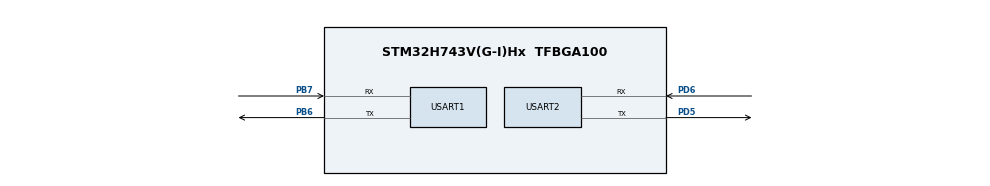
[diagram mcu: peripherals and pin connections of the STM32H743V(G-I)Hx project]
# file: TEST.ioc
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Mcu.Family=STM32H7
Mcu.Name=STM32H743V(G-I)Hx
Mcu.Package=TFBGA100
NVIC.PriorityGroup=NVIC_PRIORITYGROUP_4
NVIC.USART1_IRQn=true\:0\:0\:false\:false\:true\:true\:true\:true
NVIC.USART2_IRQn=true\:0\:0\:false\:false\:true\:true\:true\:true
PA13\ (JTMS/SWDIO).Mode=Serial_Wire
PA13\ (JTMS/SWDIO).Signal=DEBUG_JTMS-SWDIO
PA14\ (JTCK/SWCLK).Mode=Serial_Wire
PA14\ (JTCK/SWCLK).Signal=DEBUG_JTCK-SWCLK
PB6.Mode=Asynchronous
PB6.Signal=USART1_TX
PB7.Mode=Asynchronous
PB7.Signal=USART1_RX
PD5.Mode=Asynchronous
PD5.Signal=USART2_TX
PD6.Mode=Asynchronous
PD6.Signal=USART2_RX
PH0-OSC_IN\ (PH0).Mode=HSE-External-Oscillator
PH0-OSC_IN\ (PH0).Signal=RCC_OSC_IN
PH1-OSC_OUT\ (PH1).Mode=HSE-External-Oscillator
PH1-OSC_OUT\ (PH1).Signal=RCC_OSC_OUT
ProjectManager.HeapSize=0x200
ProjectManager.StackSize=0x400
ProjectManager.TargetToolchain=STM32CubeIDE
RCC.ADCFreq_Value=129000000
RCC.APB1Freq_Value=25000000
RCC.APB2Freq_Value=25000000
RCC.APB3Freq_Value=25000000
RCC.APB4Freq_Value=25000000
RCC.CortexFreq_Value=100000000
RCC.D1PPRE=RCC_APB3_DIV2
RCC.D2PPRE1=RCC_APB1_DIV2
RCC.D2PPRE2=RCC_APB2_DIV2
RCC.D3PPRE=RCC_APB4_DIV2
RCC.DIVM1=4
RCC.DIVN1=12
RCC.HCLKFreq_Value=50000000
RCC.HPRE=RCC_HCLK_DIV2
RCC.HSE_VALUE=25000000
RCC.PLL2FRACN=0
RCC.PLL3FRACN=0
RCC.PLLFRACN=4096
RCC.SYSCLKFreq_VALUE=100000000
RCC.SYSCLKSource=RCC_SYSCLKSOURCE_PLLCLK
RCC.USBFreq_Value=100000000
USART1.VirtualMode-Asynchronous=VM_ASYNC
USART2.VirtualMode-Asynchronous=VM_ASYNC
board=custom

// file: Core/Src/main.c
/* USER CODE BEGIN Header */
/**
  ******************************************************************************
  * @file           : main.c
  * @brief          : Main program body
  ******************************************************************************
  * @attention
  *
  * Copyright (c) 2024 STMicroelectronics.
  * All rights reserved.
  *
  * This software is licensed under terms that can be found in the LICENSE file
  * in the root directory of this software component.
  * If no LICENSE file comes with this software, it is provided AS-IS.
  *
  ******************************************************************************
  */
/* USER CODE END Header */
#include "main.h"

UART_HandleTypeDef huart1;
UART_HandleTypeDef huart2;

void SystemClock_Config(void);
static void MX_GPIO_Init(void);
static void MX_USART1_UART_Init(void);
static void MX_USART2_UART_Init(void);

/* USER CODE BEGIN 0 */
uint8_t usart1_buf[6];

/* USER CODE END 0 */

int main(void)
{

  /* MCU Configuration--------------------------------------------------------*/

  /* Reset of all peripherals, Initializes the Flash interface and the Systick. */
  HAL_Init();

  /* Configure the system clock */
  SystemClock_Config();

  /* Initialize all configured peripherals */
  MX_GPIO_Init();
  MX_USART1_UART_Init();
  MX_USART2_UART_Init();

  /* Infinite loop */
  while (1)
  {

  }
}

void SystemClock_Config(void)
{
  RCC_OscInitTypeDef RCC_OscInitStruct = {0};
  RCC_ClkInitTypeDef RCC_ClkInitStruct = {0};

  /** Supply configuration update enable
  */
  HAL_PWREx_ConfigSupply(PWR_LDO_SUPPLY);

  /** Configure the main internal regulator output voltage
  */
  __HAL_PWR_VOLTAGESCALING_CONFIG(PWR_REGULATOR_VOLTAGE_SCALE3);

  while(!__HAL_PWR_GET_FLAG(PWR_FLAG_VOSRDY)) {}

  /** Initializes the RCC Oscillators according to the specified parameters
  * in the RCC_OscInitTypeDef structure.
  */
  RCC_OscInitStruct.OscillatorType = RCC_OSCILLATORTYPE_HSI;
  RCC_OscInitStruct.HSIState = RCC_HSI_DIV1;
  RCC_OscInitStruct.HSICalibrationValue = RCC_HSICALIBRATION_DEFAULT;
  RCC_OscInitStruct.PLL.PLLState = RCC_PLL_ON;
  RCC_OscInitStruct.PLL.PLLSource = RCC_PLLSOURCE_HSI;
  RCC_OscInitStruct.PLL.PLLM = 4;
  RCC_OscInitStruct.PLL.PLLN = 12;
  RCC_OscInitStruct.PLL.PLLP = 2;
  RCC_OscInitStruct.PLL.PLLQ = 2;
  RCC_OscInitStruct.PLL.PLLR = 2;
  RCC_OscInitStruct.PLL.PLLRGE = RCC_PLL1VCIRANGE_3;
  RCC_OscInitStruct.PLL.PLLVCOSEL = RCC_PLL1VCOWIDE;
  RCC_OscInitStruct.PLL.PLLFRACN = 4096;
  if (HAL_RCC_OscConfig(&RCC_OscInitStruct) != HAL_OK)
  {
    Error_Handler();
  }

  /** Initializes the CPU, AHB and APB buses clocks
  */
  RCC_ClkInitStruct.ClockType = RCC_CLOCKTYPE_HCLK|RCC_CLOCKTYPE_SYSCLK
                              |RCC_CLOCKTYPE_PCLK1|RCC_CLOCKTYPE_PCLK2
                              |RCC_CLOCKTYPE_D3PCLK1|RCC_CLOCKTYPE_D1PCLK1;
  RCC_ClkInitStruct.SYSCLKSource = RCC_SYSCLKSOURCE_PLLCLK;
  RCC_ClkInitStruct.SYSCLKDivider = RCC_SYSCLK_DIV1;
  RCC_ClkInitStruct.AHBCLKDivider = RCC_HCLK_DIV2;
  RCC_ClkInitStruct.APB3CLKDivider = RCC_APB3_DIV2;
  RCC_ClkInitStruct.APB1CLKDivider = RCC_APB1_DIV2;
  RCC_ClkInitStruct.APB2CLKDivider = RCC_APB2_DIV2;
  RCC_ClkInitStruct.APB4CLKDivider = RCC_APB4_DIV2;

  if (HAL_RCC_ClockConfig(&RCC_ClkInitStruct, FLASH_LATENCY_1) != HAL_OK)
  {
    Error_Handler();
  }
}

static void MX_USART1_UART_Init(void)
{

  huart1.Instance = USART1;
  huart1.Init.BaudRate = 115200;
  huart1.Init.WordLength = UART_WORDLENGTH_8B;
  huart1.Init.StopBits = UART_STOPBITS_1;
  huart1.Init.Parity = UART_PARITY_NONE;
  huart1.Init.Mode = UART_MODE_TX_RX;
  huart1.Init.HwFlowCtl = UART_HWCONTROL_NONE;
  huart1.Init.OverSampling = UART_OVERSAMPLING_16;
  huart1.Init.OneBitSampling = UART_ONE_BIT_SAMPLE_DISABLE;
  huart1.Init.ClockPrescaler = UART_PRESCALER_DIV1;
  huart1.AdvancedInit.AdvFeatureInit = UART_ADVFEATURE_NO_INIT;
  if (HAL_UART_Init(&huart1) != HAL_OK)
  {
    Error_Handler();
  }
  if (HAL_UARTEx_SetTxFifoThreshold(&huart1, UART_TXFIFO_THRESHOLD_1_8) != HAL_OK)
  {
    Error_Handler();
  }
  if (HAL_UARTEx_SetRxFifoThreshold(&huart1, UART_RXFIFO_THRESHOLD_1_8) != HAL_OK)
  {
    Error_Handler();
  }
  if (HAL_UARTEx_DisableFifoMode(&huart1) != HAL_OK)
  {
    Error_Handler();
  }

}

static void MX_USART2_UART_Init(void)
{

  huart2.Instance = USART2;
  huart2.Init.BaudRate = 115200;
  huart2.Init.WordLength = UART_WORDLENGTH_8B;
  huart2.Init.StopBits = UART_STOPBITS_1;
  huart2.Init.Parity = UART_PARITY_NONE;
  huart2.Init.Mode = UART_MODE_TX_RX;
  huart2.Init.HwFlowCtl = UART_HWCONTROL_NONE;
  huart2.Init.OverSampling = UART_OVERSAMPLING_16;
  huart2.Init.OneBitSampling = UART_ONE_BIT_SAMPLE_DISABLE;
  huart2.Init.ClockPrescaler = UART_PRESCALER_DIV1;
  huart2.AdvancedInit.AdvFeatureInit = UART_ADVFEATURE_NO_INIT;
  if (HAL_UART_Init(&huart2) != HAL_OK)
  {
    Error_Handler();
  }
  if (HAL_UARTEx_SetTxFifoThreshold(&huart2, UART_TXFIFO_THRESHOLD_1_8) != HAL_OK)
  {
    Error_Handler();
  }
  if (HAL_UARTEx_SetRxFifoThreshold(&huart2, UART_RXFIFO_THRESHOLD_1_8) != HAL_OK)
  {
    Error_Handler();
  }
  if (HAL_UARTEx_DisableFifoMode(&huart2) != HAL_OK)
  {
    Error_Handler();
  }

}

static void MX_GPIO_Init(void)
{

  /* GPIO Ports Clock Enable */
  __HAL_RCC_GPIOB_CLK_ENABLE();
  __HAL_RCC_GPIOA_CLK_ENABLE();
  __HAL_RCC_GPIOD_CLK_ENABLE();
  __HAL_RCC_GPIOH_CLK_ENABLE();

}

void Error_Handler(void)
{
  __disable_irq();
  while (1)
  {
  }
}
